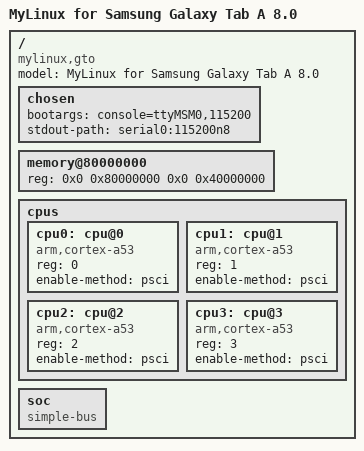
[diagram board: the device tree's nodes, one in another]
/dts-v1/;

/ {
    model = "MyLinux for Samsung Galaxy Tab A 8.0";
    compatible = "mylinux,gto", "samsung,gto";

    #address-cells = <2>;
    #size-cells = <2>;

    chosen {
        bootargs = "console=ttyMSM0,115200";
        stdout-path = "serial0:115200n8";
    };

    memory@80000000 {
        device_type = "memory";
        reg = <0x0 0x80000000 0x0 0x40000000>;
    };

    cpus {
        #address-cells = <1>;
        #size-cells = <0>;

        cpu0: cpu@0 {
            device_type = "cpu";
            compatible = "arm,cortex-a53";
            reg = <0>;
            enable-method = "psci";
        };

        cpu1: cpu@1 {
            device_type = "cpu";
            compatible = "arm,cortex-a53";
            reg = <1>;
            enable-method = "psci";
        };

        cpu2: cpu@2 {
            device_type = "cpu";
            compatible = "arm,cortex-a53";
            reg = <2>;
            enable-method = "psci";
        };

        cpu3: cpu@3 {
            device_type = "cpu";
            compatible = "arm,cortex-a53";
            reg = <3>;
            enable-method = "psci";
        };
    };

    soc {
        compatible = "simple-bus";
        #address-cells = <2>;
        #size-cells = <2>;
        ranges;
    };

    /*
     * Component files are included at the root level.
     * Add each file as it is created.
     */

    #include "gto-device-info.dtsi"
    #include "gto-clocks.dtsi"
    #include "gto-regulators.dtsi"
    #include "gto-battery.dtsi"
    #include "gto-display.dtsi"
    #include "gto-gpu.dtsi"
    #include "gto-storage.dtsi"
    #include "gto-usb.dtsi"
    #include "gto-wifi.dtsi"
    #include "gto-audio.dtsi"
};
